# MSS_CTRL_MSS_CTRL_50D00000h register map
Vendor: Texas Instruments
Registers are 32-bit, read-only, reset values left out (the file's numbers can be read two ways) unless marked. A register's access mark holds for its fields unless they carry their own. Offsets are as the file gives them; [hi:lo] are bit positions.

## MSS_CTRL (part 5 of 10)
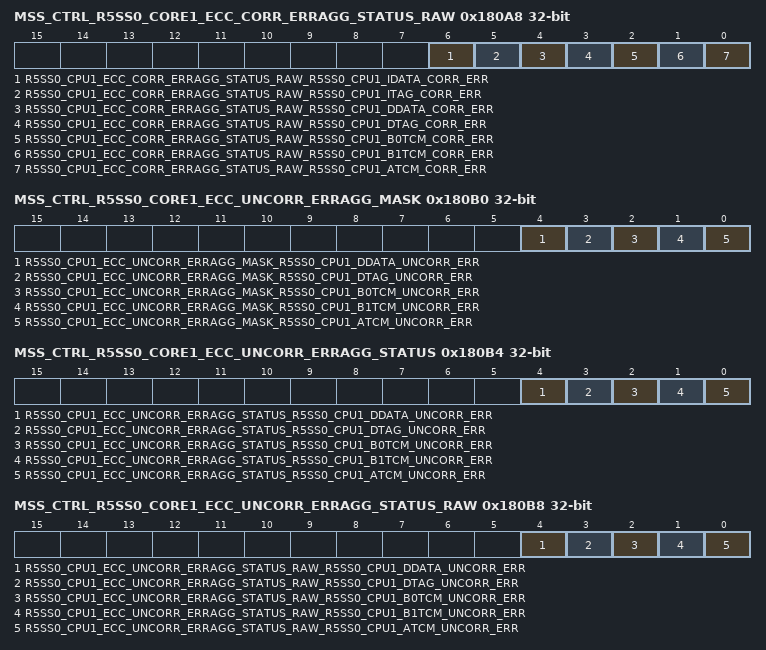
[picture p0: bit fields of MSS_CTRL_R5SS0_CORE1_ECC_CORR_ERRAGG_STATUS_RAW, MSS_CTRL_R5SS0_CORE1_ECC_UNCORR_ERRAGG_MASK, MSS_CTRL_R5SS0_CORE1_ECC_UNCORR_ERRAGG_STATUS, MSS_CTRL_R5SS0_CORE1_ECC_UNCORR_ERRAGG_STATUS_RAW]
0x180A8 MSS_CTRL_R5SS0_CORE1_ECC_CORR_ERRAGG_STATUS_RAW rw — Raw status for correctable error from R5SS0 CORE1 Memories.
  [6] R5SS0_CPU1_ECC_CORR_ERRAGG_STATUS_RAW_R5SS0_CPU1_IDATA_CORR_ERR — Raw Status of Interrupt from correctable error of corresponding CPUSet only if Interupt is unmasked in corresponding R5SS*_CPU*_ECC_CORR_ERRAGG_MASK registerWrie 0x1 to clear this interrupt.
  [5] R5SS0_CPU1_ECC_CORR_ERRAGG_STATUS_RAW_R5SS0_CPU1_ITAG_CORR_ERR — Raw Status of Interrupt from correctable error of corresponding CPUSet only if Interupt is unmasked in corresponding R5SS*_CPU*_ECC_CORR_ERRAGG_MASK registerWrie 0x1 to clear this interrupt.
  [4] R5SS0_CPU1_ECC_CORR_ERRAGG_STATUS_RAW_R5SS0_CPU1_DDATA_CORR_ERR — Raw Status of Interrupt from correctable error of corresponding CPUSet only if Interupt is unmasked in corresponding R5SS*_CPU*_ECC_CORR_ERRAGG_MASK registerWrie 0x1 to clear this interrupt.
  [3] R5SS0_CPU1_ECC_CORR_ERRAGG_STATUS_RAW_R5SS0_CPU1_DTAG_CORR_ERR — Raw Status of Interrupt from correctable error of corresponding CPUSet only if Interupt is unmasked in corresponding R5SS*_CPU*_ECC_CORR_ERRAGG_MASK registerWrie 0x1 to clear this interrupt.
  [2] R5SS0_CPU1_ECC_CORR_ERRAGG_STATUS_RAW_R5SS0_CPU1_B0TCM_CORR_ERR — Raw Status of Interrupt from correctable error of corresponding CPUSet only if Interupt is unmasked in corresponding R5SS*_CPU*_ECC_CORR_ERRAGG_MASK registerWrie 0x1 to clear this interrupt.
  [1] R5SS0_CPU1_ECC_CORR_ERRAGG_STATUS_RAW_R5SS0_CPU1_B1TCM_CORR_ERR — Raw Status of Interrupt from correctable error of corresponding CPUSet only if Interupt is unmasked in corresponding R5SS*_CPU*_ECC_CORR_ERRAGG_MASK registerWrie 0x1 to clear this interrupt.
  [0] R5SS0_CPU1_ECC_CORR_ERRAGG_STATUS_RAW_R5SS0_CPU1_ATCM_CORR_ERR — Raw Status of Interrupt from correctable error of corresponding CPUSet only if Interupt is unmasked in corresponding R5SS*_CPU*_ECC_CORR_ERRAGG_MASK registerWrie 0x1 to clear this interrupt.
0x180B0 MSS_CTRL_R5SS0_CORE1_ECC_UNCORR_ERRAGG_MASK rw — Register to Mask Uncorrectable error from R5SS0 CORE1 Memories.
  [4] R5SS0_CPU1_ECC_UNCORR_ERRAGG_MASK_R5SS0_CPU1_DDATA_UNCORR_ERR — Mask Interrupt for correctable errors to aggregated Interrupt of corresponding CPU1'b1 : Interrupt is Masked1'b0 : Interrupt is Unmasked
  [3] R5SS0_CPU1_ECC_UNCORR_ERRAGG_MASK_R5SS0_CPU1_DTAG_UNCORR_ERR — Mask Interrupt for correctable errors to aggregated Interrupt of corresponding CPU1'b1 : Interrupt is Masked1'b0 : Interrupt is Unmasked
  [2] R5SS0_CPU1_ECC_UNCORR_ERRAGG_MASK_R5SS0_CPU1_B0TCM_UNCORR_ERR — Mask Interrupt for correctable errors to aggregated Interrupt of corresponding CPU1'b1 : Interrupt is Masked1'b0 : Interrupt is Unmasked
  [1] R5SS0_CPU1_ECC_UNCORR_ERRAGG_MASK_R5SS0_CPU1_B1TCM_UNCORR_ERR — Mask Interrupt for correctable errors to aggregated Interrupt of corresponding CPU1'b1 : Interrupt is Masked1'b0 : Interrupt is Unmasked
  [0] R5SS0_CPU1_ECC_UNCORR_ERRAGG_MASK_R5SS0_CPU1_ATCM_UNCORR_ERR — Mask Interrupt for correctable errors to aggregated Interrupt of corresponding CPU1'b1 : Interrupt is Masked1'b0 : Interrupt is Unmasked
0x180B4 MSS_CTRL_R5SS0_CORE1_ECC_UNCORR_ERRAGG_STATUS rw — Status register based on mask for uncorrectable error R5SS0 CORE1 Memories.
  [4] R5SS0_CPU1_ECC_UNCORR_ERRAGG_STATUS_R5SS0_CPU1_DDATA_UNCORR_ERR — Status of Interrupt from correctable error of corresponding CPUSet only if Interupt is unmasked in corresponding R5SS*_CPU*_ECC_UNCORR_ERRAGG_MASK registerWrie 0x1 to clear this interrupt.
  [3] R5SS0_CPU1_ECC_UNCORR_ERRAGG_STATUS_R5SS0_CPU1_DTAG_UNCORR_ERR — Status of Interrupt from correctable error of corresponding CPUSet only if Interupt is unmasked in corresponding R5SS*_CPU*_ECC_UNCORR_ERRAGG_MASK registerWrie 0x1 to clear this interrupt.
  [2] R5SS0_CPU1_ECC_UNCORR_ERRAGG_STATUS_R5SS0_CPU1_B0TCM_UNCORR_ERR — Status of Interrupt from correctable error of corresponding CPUSet only if Interupt is unmasked in corresponding R5SS*_CPU*_ECC_UNCORR_ERRAGG_MASK registerWrie 0x1 to clear this interrupt.
  [1] R5SS0_CPU1_ECC_UNCORR_ERRAGG_STATUS_R5SS0_CPU1_B1TCM_UNCORR_ERR — Status of Interrupt from correctable error of corresponding CPUSet only if Interupt is unmasked in corresponding R5SS*_CPU*_ECC_UNCORR_ERRAGG_MASK registerWrie 0x1 to clear this interrupt.
  [0] R5SS0_CPU1_ECC_UNCORR_ERRAGG_STATUS_R5SS0_CPU1_ATCM_UNCORR_ERR — Status of Interrupt from correctable error of corresponding CPUSet only if Interupt is unmasked in corresponding R5SS*_CPU*_ECC_UNCORR_ERRAGG_MASK registerWrie 0x1 to clear this interrupt.
0x180B8 MSS_CTRL_R5SS0_CORE1_ECC_UNCORR_ERRAGG_STATUS_RAW rw — Raw status for uncorrectable error from R5SS0 CORE1 Memories.
  [4] R5SS0_CPU1_ECC_UNCORR_ERRAGG_STATUS_RAW_R5SS0_CPU1_DDATA_UNCORR_ERR — Raw Status of Interrupt from correctable error of corresponding CPUSet only if Interupt is unmasked in corresponding R5SS*_CPU*_ECC_UNCORR_ERRAGG_MASK registerWrie 0x1 to clear this interrupt.
  [3] R5SS0_CPU1_ECC_UNCORR_ERRAGG_STATUS_RAW_R5SS0_CPU1_DTAG_UNCORR_ERR — Raw Status of Interrupt from correctable error of corresponding CPUSet only if Interupt is unmasked in corresponding R5SS*_CPU*_ECC_UNCORR_ERRAGG_MASK registerWrie 0x1 to clear this interrupt.
  [2] R5SS0_CPU1_ECC_UNCORR_ERRAGG_STATUS_RAW_R5SS0_CPU1_B0TCM_UNCORR_ERR — Raw Status of Interrupt from correctable error of corresponding CPUSet only if Interupt is unmasked in corresponding R5SS*_CPU*_ECC_UNCORR_ERRAGG_MASK registerWrie 0x1 to clear this interrupt.
  [1] R5SS0_CPU1_ECC_UNCORR_ERRAGG_STATUS_RAW_R5SS0_CPU1_B1TCM_UNCORR_ERR — Raw Status of Interrupt from correctable error of corresponding CPUSet only if Interupt is unmasked in corresponding R5SS*_CPU*_ECC_UNCORR_ERRAGG_MASK registerWrie 0x1 to clear this interrupt.
  [0] R5SS0_CPU1_ECC_UNCORR_ERRAGG_STATUS_RAW_R5SS0_CPU1_ATCM_UNCORR_ERR — Raw Status of Interrupt from correctable error of corresponding CPUSet only if Interupt is unmasked in corresponding R5SS*_CPU*_ECC_UNCORR_ERRAGG_MASK registerWrie 0x1 to clear this interrupt.
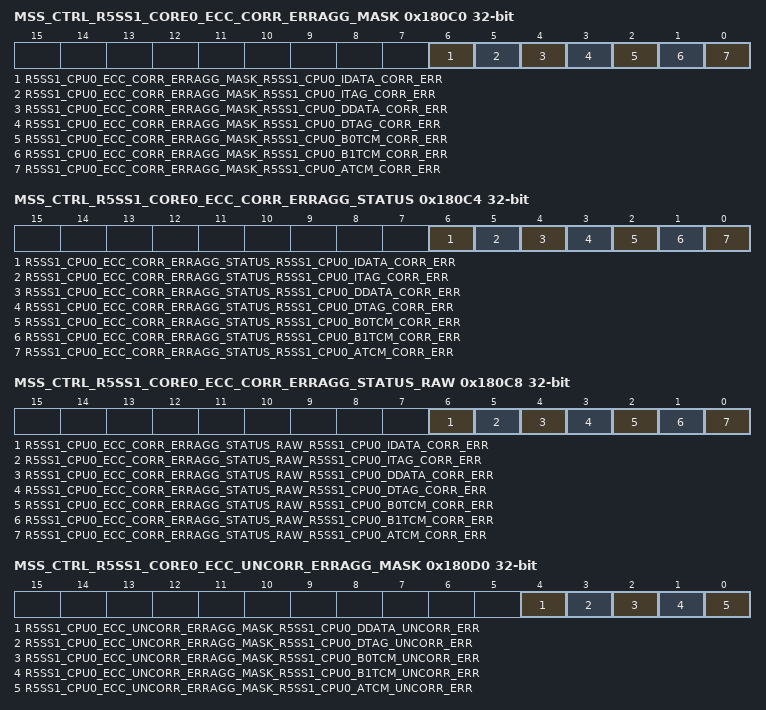
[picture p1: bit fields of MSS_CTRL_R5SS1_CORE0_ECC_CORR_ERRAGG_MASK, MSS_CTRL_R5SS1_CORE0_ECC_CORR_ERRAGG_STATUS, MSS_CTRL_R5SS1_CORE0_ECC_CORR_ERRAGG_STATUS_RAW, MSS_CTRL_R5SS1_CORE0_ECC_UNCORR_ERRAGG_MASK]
0x180C0 MSS_CTRL_R5SS1_CORE0_ECC_CORR_ERRAGG_MASK rw — Register to Mask Correctable error from R5SS1 CORE0 Memories.
  [6] R5SS1_CPU0_ECC_CORR_ERRAGG_MASK_R5SS1_CPU0_IDATA_CORR_ERR — Mask Interrupt for correctable errors to aggregated Interrupt of corresponding CPU1'b1 : Interrupt is Masked1'b0 : Interrupt is Unmasked
  [5] R5SS1_CPU0_ECC_CORR_ERRAGG_MASK_R5SS1_CPU0_ITAG_CORR_ERR — Mask Interrupt for correctable errors to aggregated Interrupt of corresponding CPU1'b1 : Interrupt is Masked1'b0 : Interrupt is Unmasked
  [4] R5SS1_CPU0_ECC_CORR_ERRAGG_MASK_R5SS1_CPU0_DDATA_CORR_ERR — Mask Interrupt for correctable errors to aggregated Interrupt of corresponding CPU1'b1 : Interrupt is Masked1'b0 : Interrupt is Unmasked
  [3] R5SS1_CPU0_ECC_CORR_ERRAGG_MASK_R5SS1_CPU0_DTAG_CORR_ERR — Mask Interrupt for correctable errors to aggregated Interrupt of corresponding CPU1'b1 : Interrupt is Masked1'b0 : Interrupt is Unmasked
  [2] R5SS1_CPU0_ECC_CORR_ERRAGG_MASK_R5SS1_CPU0_B0TCM_CORR_ERR — Mask Interrupt for correctable errors to aggregated Interrupt of corresponding CPU1'b1 : Interrupt is Masked1'b0 : Interrupt is Unmasked
  [1] R5SS1_CPU0_ECC_CORR_ERRAGG_MASK_R5SS1_CPU0_B1TCM_CORR_ERR — Mask Interrupt for correctable errors to aggregated Interrupt of corresponding CPU1'b1 : Interrupt is Masked1'b0 : Interrupt is Unmasked
  [0] R5SS1_CPU0_ECC_CORR_ERRAGG_MASK_R5SS1_CPU0_ATCM_CORR_ERR — Mask Interrupt for correctable errors to aggregated Interrupt of corresponding CPU1'b1 : Interrupt is Masked1'b0 : Interrupt is Unmasked
0x180C4 MSS_CTRL_R5SS1_CORE0_ECC_CORR_ERRAGG_STATUS rw — Status register based on mask for correctable error R5SS1 CORE0 Memories.
  [6] R5SS1_CPU0_ECC_CORR_ERRAGG_STATUS_R5SS1_CPU0_IDATA_CORR_ERR — Status of Interrupt from correctable error of corresponding CPUSet only if Interupt is unmasked in corresponding R5SS*_CPU*_ECC_CORR_ERRAGG_MASK registerWrie 0x1 to clear this interrupt.
  [5] R5SS1_CPU0_ECC_CORR_ERRAGG_STATUS_R5SS1_CPU0_ITAG_CORR_ERR — Status of Interrupt from correctable error of corresponding CPUSet only if Interupt is unmasked in corresponding R5SS*_CPU*_ECC_CORR_ERRAGG_MASK registerWrie 0x1 to clear this interrupt.
  [4] R5SS1_CPU0_ECC_CORR_ERRAGG_STATUS_R5SS1_CPU0_DDATA_CORR_ERR — Status of Interrupt from correctable error of corresponding CPUSet only if Interupt is unmasked in corresponding R5SS*_CPU*_ECC_CORR_ERRAGG_MASK registerWrie 0x1 to clear this interrupt.
  [3] R5SS1_CPU0_ECC_CORR_ERRAGG_STATUS_R5SS1_CPU0_DTAG_CORR_ERR — Status of Interrupt from correctable error of corresponding CPUSet only if Interupt is unmasked in corresponding R5SS*_CPU*_ECC_CORR_ERRAGG_MASK registerWrie 0x1 to clear this interrupt.
  [2] R5SS1_CPU0_ECC_CORR_ERRAGG_STATUS_R5SS1_CPU0_B0TCM_CORR_ERR — Status of Interrupt from correctable error of corresponding CPUSet only if Interupt is unmasked in corresponding R5SS*_CPU*_ECC_CORR_ERRAGG_MASK registerWrie 0x1 to clear this interrupt.
  [1] R5SS1_CPU0_ECC_CORR_ERRAGG_STATUS_R5SS1_CPU0_B1TCM_CORR_ERR — Status of Interrupt from correctable error of corresponding CPUSet only if Interupt is unmasked in corresponding R5SS*_CPU*_ECC_CORR_ERRAGG_MASK registerWrie 0x1 to clear this interrupt.
  [0] R5SS1_CPU0_ECC_CORR_ERRAGG_STATUS_R5SS1_CPU0_ATCM_CORR_ERR — Status of Interrupt from correctable error of corresponding CPUSet only if Interupt is unmasked in corresponding R5SS*_CPU*_ECC_CORR_ERRAGG_MASK registerWrie 0x1 to clear this interrupt.
0x180C8 MSS_CTRL_R5SS1_CORE0_ECC_CORR_ERRAGG_STATUS_RAW rw — Raw status for correctable error from R5SS1 CORE0 Memories.
  [6] R5SS1_CPU0_ECC_CORR_ERRAGG_STATUS_RAW_R5SS1_CPU0_IDATA_CORR_ERR — Raw Status of Interrupt from correctable error of corresponding CPUSet only if Interupt is unmasked in corresponding R5SS*_CPU*_ECC_CORR_ERRAGG_MASK registerWrie 0x1 to clear this interrupt.
  [5] R5SS1_CPU0_ECC_CORR_ERRAGG_STATUS_RAW_R5SS1_CPU0_ITAG_CORR_ERR — Raw Status of Interrupt from correctable error of corresponding CPUSet only if Interupt is unmasked in corresponding R5SS*_CPU*_ECC_CORR_ERRAGG_MASK registerWrie 0x1 to clear this interrupt.
  [4] R5SS1_CPU0_ECC_CORR_ERRAGG_STATUS_RAW_R5SS1_CPU0_DDATA_CORR_ERR — Raw Status of Interrupt from correctable error of corresponding CPUSet only if Interupt is unmasked in corresponding R5SS*_CPU*_ECC_CORR_ERRAGG_MASK registerWrie 0x1 to clear this interrupt.
  [3] R5SS1_CPU0_ECC_CORR_ERRAGG_STATUS_RAW_R5SS1_CPU0_DTAG_CORR_ERR — Raw Status of Interrupt from correctable error of corresponding CPUSet only if Interupt is unmasked in corresponding R5SS*_CPU*_ECC_CORR_ERRAGG_MASK registerWrie 0x1 to clear this interrupt.
  [2] R5SS1_CPU0_ECC_CORR_ERRAGG_STATUS_RAW_R5SS1_CPU0_B0TCM_CORR_ERR — Raw Status of Interrupt from correctable error of corresponding CPUSet only if Interupt is unmasked in corresponding R5SS*_CPU*_ECC_CORR_ERRAGG_MASK registerWrie 0x1 to clear this interrupt.
  [1] R5SS1_CPU0_ECC_CORR_ERRAGG_STATUS_RAW_R5SS1_CPU0_B1TCM_CORR_ERR — Raw Status of Interrupt from correctable error of corresponding CPUSet only if Interupt is unmasked in corresponding R5SS*_CPU*_ECC_CORR_ERRAGG_MASK registerWrie 0x1 to clear this interrupt.
  [0] R5SS1_CPU0_ECC_CORR_ERRAGG_STATUS_RAW_R5SS1_CPU0_ATCM_CORR_ERR — Raw Status of Interrupt from correctable error of corresponding CPUSet only if Interupt is unmasked in corresponding R5SS*_CPU*_ECC_CORR_ERRAGG_MASK registerWrie 0x1 to clear this interrupt.
0x180D0 MSS_CTRL_R5SS1_CORE0_ECC_UNCORR_ERRAGG_MASK rw — Register to Mask Uncorrectable error from R5SS1 CORE0 Memories.
  [4] R5SS1_CPU0_ECC_UNCORR_ERRAGG_MASK_R5SS1_CPU0_DDATA_UNCORR_ERR — Mask Interrupt for correctable errors to aggregated Interrupt of corresponding CPU1'b1 : Interrupt is Masked1'b0 : Interrupt is Unmasked
  [3] R5SS1_CPU0_ECC_UNCORR_ERRAGG_MASK_R5SS1_CPU0_DTAG_UNCORR_ERR — Mask Interrupt for correctable errors to aggregated Interrupt of corresponding CPU1'b1 : Interrupt is Masked1'b0 : Interrupt is Unmasked
  [2] R5SS1_CPU0_ECC_UNCORR_ERRAGG_MASK_R5SS1_CPU0_B0TCM_UNCORR_ERR — Mask Interrupt for correctable errors to aggregated Interrupt of corresponding CPU1'b1 : Interrupt is Masked1'b0 : Interrupt is Unmasked
  [1] R5SS1_CPU0_ECC_UNCORR_ERRAGG_MASK_R5SS1_CPU0_B1TCM_UNCORR_ERR — Mask Interrupt for correctable errors to aggregated Interrupt of corresponding CPU1'b1 : Interrupt is Masked1'b0 : Interrupt is Unmasked
  [0] R5SS1_CPU0_ECC_UNCORR_ERRAGG_MASK_R5SS1_CPU0_ATCM_UNCORR_ERR — Mask Interrupt for correctable errors to aggregated Interrupt of corresponding CPU1'b1 : Interrupt is Masked1'b0 : Interrupt is Unmasked
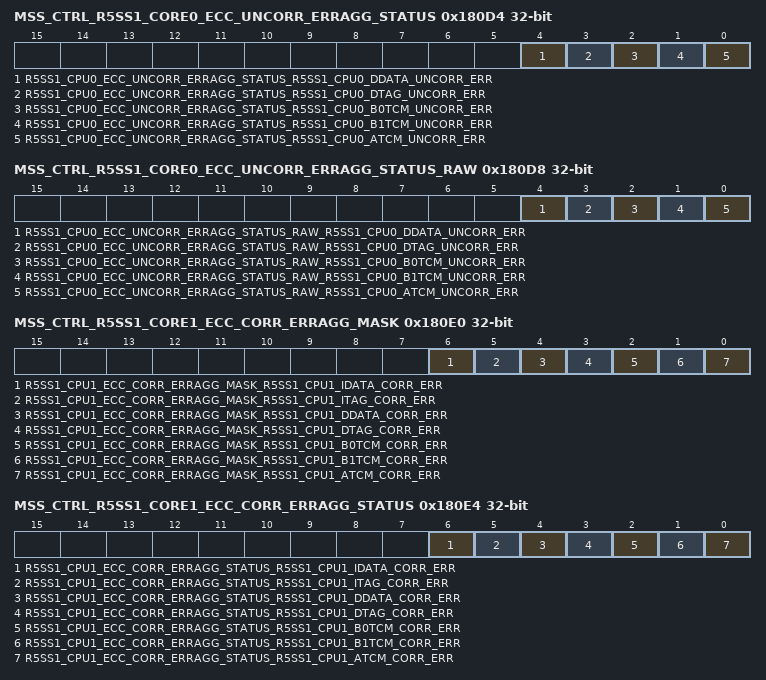
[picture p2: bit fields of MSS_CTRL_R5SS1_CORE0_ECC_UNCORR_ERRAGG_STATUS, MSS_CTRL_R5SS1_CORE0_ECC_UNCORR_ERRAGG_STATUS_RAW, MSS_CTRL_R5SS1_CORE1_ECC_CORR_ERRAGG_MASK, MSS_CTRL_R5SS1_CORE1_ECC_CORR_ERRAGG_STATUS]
0x180D4 MSS_CTRL_R5SS1_CORE0_ECC_UNCORR_ERRAGG_STATUS rw — Status register based on mask for uncorrectable error R5SS1 CORE0 Memories.
  [4] R5SS1_CPU0_ECC_UNCORR_ERRAGG_STATUS_R5SS1_CPU0_DDATA_UNCORR_ERR — Status of Interrupt from correctable error of corresponding CPUSet only if Interupt is unmasked in corresponding R5SS*_CPU*_ECC_UNCORR_ERRAGG_MASK registerWrie 0x1 to clear this interrupt.
  [3] R5SS1_CPU0_ECC_UNCORR_ERRAGG_STATUS_R5SS1_CPU0_DTAG_UNCORR_ERR — Status of Interrupt from correctable error of corresponding CPUSet only if Interupt is unmasked in corresponding R5SS*_CPU*_ECC_UNCORR_ERRAGG_MASK registerWrie 0x1 to clear this interrupt.
  [2] R5SS1_CPU0_ECC_UNCORR_ERRAGG_STATUS_R5SS1_CPU0_B0TCM_UNCORR_ERR — Status of Interrupt from correctable error of corresponding CPUSet only if Interupt is unmasked in corresponding R5SS*_CPU*_ECC_UNCORR_ERRAGG_MASK registerWrie 0x1 to clear this interrupt.
  [1] R5SS1_CPU0_ECC_UNCORR_ERRAGG_STATUS_R5SS1_CPU0_B1TCM_UNCORR_ERR — Status of Interrupt from correctable error of corresponding CPUSet only if Interupt is unmasked in corresponding R5SS*_CPU*_ECC_UNCORR_ERRAGG_MASK registerWrie 0x1 to clear this interrupt.
  [0] R5SS1_CPU0_ECC_UNCORR_ERRAGG_STATUS_R5SS1_CPU0_ATCM_UNCORR_ERR — Status of Interrupt from correctable error of corresponding CPUSet only if Interupt is unmasked in corresponding R5SS*_CPU*_ECC_UNCORR_ERRAGG_MASK registerWrie 0x1 to clear this interrupt.
0x180D8 MSS_CTRL_R5SS1_CORE0_ECC_UNCORR_ERRAGG_STATUS_RAW rw — Raw status for uncorrectable error from R5SS1 CORE0 Memories.
  [4] R5SS1_CPU0_ECC_UNCORR_ERRAGG_STATUS_RAW_R5SS1_CPU0_DDATA_UNCORR_ERR — Raw Status of Interrupt from correctable error of corresponding CPUSet only if Interupt is unmasked in corresponding R5SS*_CPU*_ECC_UNCORR_ERRAGG_MASK registerWrie 0x1 to clear this interrupt.
  [3] R5SS1_CPU0_ECC_UNCORR_ERRAGG_STATUS_RAW_R5SS1_CPU0_DTAG_UNCORR_ERR — Raw Status of Interrupt from correctable error of corresponding CPUSet only if Interupt is unmasked in corresponding R5SS*_CPU*_ECC_UNCORR_ERRAGG_MASK registerWrie 0x1 to clear this interrupt.
  [2] R5SS1_CPU0_ECC_UNCORR_ERRAGG_STATUS_RAW_R5SS1_CPU0_B0TCM_UNCORR_ERR — Raw Status of Interrupt from correctable error of corresponding CPUSet only if Interupt is unmasked in corresponding R5SS*_CPU*_ECC_UNCORR_ERRAGG_MASK registerWrie 0x1 to clear this interrupt.
  [1] R5SS1_CPU0_ECC_UNCORR_ERRAGG_STATUS_RAW_R5SS1_CPU0_B1TCM_UNCORR_ERR — Raw Status of Interrupt from correctable error of corresponding CPUSet only if Interupt is unmasked in corresponding R5SS*_CPU*_ECC_UNCORR_ERRAGG_MASK registerWrie 0x1 to clear this interrupt.
  [0] R5SS1_CPU0_ECC_UNCORR_ERRAGG_STATUS_RAW_R5SS1_CPU0_ATCM_UNCORR_ERR — Raw Status of Interrupt from correctable error of corresponding CPUSet only if Interupt is unmasked in corresponding R5SS*_CPU*_ECC_UNCORR_ERRAGG_MASK registerWrie 0x1 to clear this interrupt.
0x180E0 MSS_CTRL_R5SS1_CORE1_ECC_CORR_ERRAGG_MASK rw — Register to Mask Correctable error from R5SS1 CORE1 Memories.
  [6] R5SS1_CPU1_ECC_CORR_ERRAGG_MASK_R5SS1_CPU1_IDATA_CORR_ERR — Mask Interrupt for correctable errors to aggregated Interrupt of corresponding CPU1'b1 : Interrupt is Masked1'b0 : Interrupt is Unmasked
  [5] R5SS1_CPU1_ECC_CORR_ERRAGG_MASK_R5SS1_CPU1_ITAG_CORR_ERR — Mask Interrupt for correctable errors to aggregated Interrupt of corresponding CPU1'b1 : Interrupt is Masked1'b0 : Interrupt is Unmasked
  [4] R5SS1_CPU1_ECC_CORR_ERRAGG_MASK_R5SS1_CPU1_DDATA_CORR_ERR — Mask Interrupt for correctable errors to aggregated Interrupt of corresponding CPU1'b1 : Interrupt is Masked1'b0 : Interrupt is Unmasked
  [3] R5SS1_CPU1_ECC_CORR_ERRAGG_MASK_R5SS1_CPU1_DTAG_CORR_ERR — Mask Interrupt for correctable errors to aggregated Interrupt of corresponding CPU1'b1 : Interrupt is Masked1'b0 : Interrupt is Unmasked
  [2] R5SS1_CPU1_ECC_CORR_ERRAGG_MASK_R5SS1_CPU1_B0TCM_CORR_ERR — Mask Interrupt for correctable errors to aggregated Interrupt of corresponding CPU1'b1 : Interrupt is Masked1'b0 : Interrupt is Unmasked
  [1] R5SS1_CPU1_ECC_CORR_ERRAGG_MASK_R5SS1_CPU1_B1TCM_CORR_ERR — Mask Interrupt for correctable errors to aggregated Interrupt of corresponding CPU1'b1 : Interrupt is Masked1'b0 : Interrupt is Unmasked
  [0] R5SS1_CPU1_ECC_CORR_ERRAGG_MASK_R5SS1_CPU1_ATCM_CORR_ERR — Mask Interrupt for correctable errors to aggregated Interrupt of corresponding CPU1'b1 : Interrupt is Masked1'b0 : Interrupt is Unmasked
0x180E4 MSS_CTRL_R5SS1_CORE1_ECC_CORR_ERRAGG_STATUS rw — Status register based on mask for correctable error R5SS1 CORE1 Memories.
  [6] R5SS1_CPU1_ECC_CORR_ERRAGG_STATUS_R5SS1_CPU1_IDATA_CORR_ERR — Status of Interrupt from correctable error of corresponding CPUSet only if Interupt is unmasked in corresponding R5SS*_CPU*_ECC_CORR_ERRAGG_MASK registerWrie 0x1 to clear this interrupt.
  [5] R5SS1_CPU1_ECC_CORR_ERRAGG_STATUS_R5SS1_CPU1_ITAG_CORR_ERR — Status of Interrupt from correctable error of corresponding CPUSet only if Interupt is unmasked in corresponding R5SS*_CPU*_ECC_CORR_ERRAGG_MASK registerWrie 0x1 to clear this interrupt.
  [4] R5SS1_CPU1_ECC_CORR_ERRAGG_STATUS_R5SS1_CPU1_DDATA_CORR_ERR — Status of Interrupt from correctable error of corresponding CPUSet only if Interupt is unmasked in corresponding R5SS*_CPU*_ECC_CORR_ERRAGG_MASK registerWrie 0x1 to clear this interrupt.
  [3] R5SS1_CPU1_ECC_CORR_ERRAGG_STATUS_R5SS1_CPU1_DTAG_CORR_ERR — Status of Interrupt from correctable error of corresponding CPUSet only if Interupt is unmasked in corresponding R5SS*_CPU*_ECC_CORR_ERRAGG_MASK registerWrie 0x1 to clear this interrupt.
  [2] R5SS1_CPU1_ECC_CORR_ERRAGG_STATUS_R5SS1_CPU1_B0TCM_CORR_ERR — Status of Interrupt from correctable error of corresponding CPUSet only if Interupt is unmasked in corresponding R5SS*_CPU*_ECC_CORR_ERRAGG_MASK registerWrie 0x1 to clear this interrupt.
  [1] R5SS1_CPU1_ECC_CORR_ERRAGG_STATUS_R5SS1_CPU1_B1TCM_CORR_ERR — Status of Interrupt from correctable error of corresponding CPUSet only if Interupt is unmasked in corresponding R5SS*_CPU*_ECC_CORR_ERRAGG_MASK registerWrie 0x1 to clear this interrupt.
  [0] R5SS1_CPU1_ECC_CORR_ERRAGG_STATUS_R5SS1_CPU1_ATCM_CORR_ERR — Status of Interrupt from correctable error of corresponding CPUSet only if Interupt is unmasked in corresponding R5SS*_CPU*_ECC_CORR_ERRAGG_MASK registerWrie 0x1 to clear this interrupt.
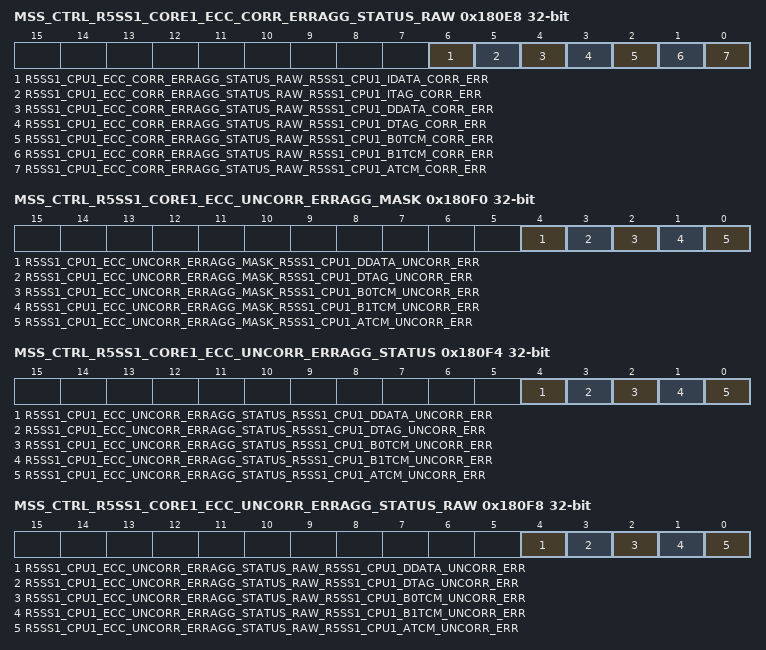
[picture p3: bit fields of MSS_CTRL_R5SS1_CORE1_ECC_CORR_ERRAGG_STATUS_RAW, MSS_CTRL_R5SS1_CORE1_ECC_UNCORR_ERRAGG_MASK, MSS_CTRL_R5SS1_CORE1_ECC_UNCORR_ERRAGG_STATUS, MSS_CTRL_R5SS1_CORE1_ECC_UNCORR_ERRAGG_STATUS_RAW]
0x180E8 MSS_CTRL_R5SS1_CORE1_ECC_CORR_ERRAGG_STATUS_RAW rw — Raw status for correctable error from R5SS1 CORE1 Memories.
  [6] R5SS1_CPU1_ECC_CORR_ERRAGG_STATUS_RAW_R5SS1_CPU1_IDATA_CORR_ERR — Raw Status of Interrupt from correctable error of corresponding CPUSet only if Interupt is unmasked in corresponding R5SS*_CPU*_ECC_CORR_ERRAGG_MASK registerWrie 0x1 to clear this interrupt.
  [5] R5SS1_CPU1_ECC_CORR_ERRAGG_STATUS_RAW_R5SS1_CPU1_ITAG_CORR_ERR — Raw Status of Interrupt from correctable error of corresponding CPUSet only if Interupt is unmasked in corresponding R5SS*_CPU*_ECC_CORR_ERRAGG_MASK registerWrie 0x1 to clear this interrupt.
  [4] R5SS1_CPU1_ECC_CORR_ERRAGG_STATUS_RAW_R5SS1_CPU1_DDATA_CORR_ERR — Raw Status of Interrupt from correctable error of corresponding CPUSet only if Interupt is unmasked in corresponding R5SS*_CPU*_ECC_CORR_ERRAGG_MASK registerWrie 0x1 to clear this interrupt.
  [3] R5SS1_CPU1_ECC_CORR_ERRAGG_STATUS_RAW_R5SS1_CPU1_DTAG_CORR_ERR — Raw Status of Interrupt from correctable error of corresponding CPUSet only if Interupt is unmasked in corresponding R5SS*_CPU*_ECC_CORR_ERRAGG_MASK registerWrie 0x1 to clear this interrupt.
  [2] R5SS1_CPU1_ECC_CORR_ERRAGG_STATUS_RAW_R5SS1_CPU1_B0TCM_CORR_ERR — Raw Status of Interrupt from correctable error of corresponding CPUSet only if Interupt is unmasked in corresponding R5SS*_CPU*_ECC_CORR_ERRAGG_MASK registerWrie 0x1 to clear this interrupt.
  [1] R5SS1_CPU1_ECC_CORR_ERRAGG_STATUS_RAW_R5SS1_CPU1_B1TCM_CORR_ERR — Raw Status of Interrupt from correctable error of corresponding CPUSet only if Interupt is unmasked in corresponding R5SS*_CPU*_ECC_CORR_ERRAGG_MASK registerWrie 0x1 to clear this interrupt.
  [0] R5SS1_CPU1_ECC_CORR_ERRAGG_STATUS_RAW_R5SS1_CPU1_ATCM_CORR_ERR — Raw Status of Interrupt from correctable error of corresponding CPUSet only if Interupt is unmasked in corresponding R5SS*_CPU*_ECC_CORR_ERRAGG_MASK registerWrie 0x1 to clear this interrupt.
0x180F0 MSS_CTRL_R5SS1_CORE1_ECC_UNCORR_ERRAGG_MASK rw — Register to Mask Uncorrectable error from R5SS1 CORE1 Memories.
  [4] R5SS1_CPU1_ECC_UNCORR_ERRAGG_MASK_R5SS1_CPU1_DDATA_UNCORR_ERR — Mask Interrupt for correctable errors to aggregated Interrupt of corresponding CPU1'b1 : Interrupt is Masked1'b0 : Interrupt is Unmasked
  [3] R5SS1_CPU1_ECC_UNCORR_ERRAGG_MASK_R5SS1_CPU1_DTAG_UNCORR_ERR — Mask Interrupt for correctable errors to aggregated Interrupt of corresponding CPU1'b1 : Interrupt is Masked1'b0 : Interrupt is Unmasked
  [2] R5SS1_CPU1_ECC_UNCORR_ERRAGG_MASK_R5SS1_CPU1_B0TCM_UNCORR_ERR — Mask Interrupt for correctable errors to aggregated Interrupt of corresponding CPU1'b1 : Interrupt is Masked1'b0 : Interrupt is Unmasked
  [1] R5SS1_CPU1_ECC_UNCORR_ERRAGG_MASK_R5SS1_CPU1_B1TCM_UNCORR_ERR — Mask Interrupt for correctable errors to aggregated Interrupt of corresponding CPU1'b1 : Interrupt is Masked1'b0 : Interrupt is Unmasked
  [0] R5SS1_CPU1_ECC_UNCORR_ERRAGG_MASK_R5SS1_CPU1_ATCM_UNCORR_ERR — Mask Interrupt for correctable errors to aggregated Interrupt of corresponding CPU1'b1 : Interrupt is Masked1'b0 : Interrupt is Unmasked
0x180F4 MSS_CTRL_R5SS1_CORE1_ECC_UNCORR_ERRAGG_STATUS rw — Status register based on mask for uncorrectable error R5SS1 CORE1 Memories.
  [4] R5SS1_CPU1_ECC_UNCORR_ERRAGG_STATUS_R5SS1_CPU1_DDATA_UNCORR_ERR — Status of Interrupt from correctable error of corresponding CPUSet only if Interupt is unmasked in corresponding R5SS*_CPU*_ECC_UNCORR_ERRAGG_MASK registerWrie 0x1 to clear this interrupt.
  [3] R5SS1_CPU1_ECC_UNCORR_ERRAGG_STATUS_R5SS1_CPU1_DTAG_UNCORR_ERR — Status of Interrupt from correctable error of corresponding CPUSet only if Interupt is unmasked in corresponding R5SS*_CPU*_ECC_UNCORR_ERRAGG_MASK registerWrie 0x1 to clear this interrupt.
  [2] R5SS1_CPU1_ECC_UNCORR_ERRAGG_STATUS_R5SS1_CPU1_B0TCM_UNCORR_ERR — Status of Interrupt from correctable error of corresponding CPUSet only if Interupt is unmasked in corresponding R5SS*_CPU*_ECC_UNCORR_ERRAGG_MASK registerWrie 0x1 to clear this interrupt.
  [1] R5SS1_CPU1_ECC_UNCORR_ERRAGG_STATUS_R5SS1_CPU1_B1TCM_UNCORR_ERR — Status of Interrupt from correctable error of corresponding CPUSet only if Interupt is unmasked in corresponding R5SS*_CPU*_ECC_UNCORR_ERRAGG_MASK registerWrie 0x1 to clear this interrupt.
  [0] R5SS1_CPU1_ECC_UNCORR_ERRAGG_STATUS_R5SS1_CPU1_ATCM_UNCORR_ERR — Status of Interrupt from correctable error of corresponding CPUSet only if Interupt is unmasked in corresponding R5SS*_CPU*_ECC_UNCORR_ERRAGG_MASK registerWrie 0x1 to clear this interrupt.
0x180F8 MSS_CTRL_R5SS1_CORE1_ECC_UNCORR_ERRAGG_STATUS_RAW rw — Raw status for uncorrectable error from R5SS1 CORE1 Memories.
  [4] R5SS1_CPU1_ECC_UNCORR_ERRAGG_STATUS_RAW_R5SS1_CPU1_DDATA_UNCORR_ERR — Raw Status of Interrupt from correctable error of corresponding CPUSet only if Interupt is unmasked in corresponding R5SS*_CPU*_ECC_UNCORR_ERRAGG_MASK registerWrie 0x1 to clear this interrupt.
  [3] R5SS1_CPU1_ECC_UNCORR_ERRAGG_STATUS_RAW_R5SS1_CPU1_DTAG_UNCORR_ERR — Raw Status of Interrupt from correctable error of corresponding CPUSet only if Interupt is unmasked in corresponding R5SS*_CPU*_ECC_UNCORR_ERRAGG_MASK registerWrie 0x1 to clear this interrupt.
  [2] R5SS1_CPU1_ECC_UNCORR_ERRAGG_STATUS_RAW_R5SS1_CPU1_B0TCM_UNCORR_ERR — Raw Status of Interrupt from correctable error of corresponding CPUSet only if Interupt is unmasked in corresponding R5SS*_CPU*_ECC_UNCORR_ERRAGG_MASK registerWrie 0x1 to clear this interrupt.
  [1] R5SS1_CPU1_ECC_UNCORR_ERRAGG_STATUS_RAW_R5SS1_CPU1_B1TCM_UNCORR_ERR — Raw Status of Interrupt from correctable error of corresponding CPUSet only if Interupt is unmasked in corresponding R5SS*_CPU*_ECC_UNCORR_ERRAGG_MASK registerWrie 0x1 to clear this interrupt.
  [0] R5SS1_CPU1_ECC_UNCORR_ERRAGG_STATUS_RAW_R5SS1_CPU1_ATCM_UNCORR_ERR — Raw Status of Interrupt from correctable error of corresponding CPUSet only if Interupt is unmasked in corresponding R5SS*_CPU*_ECC_UNCORR_ERRAGG_MASK registerWrie 0x1 to clear this interrupt.
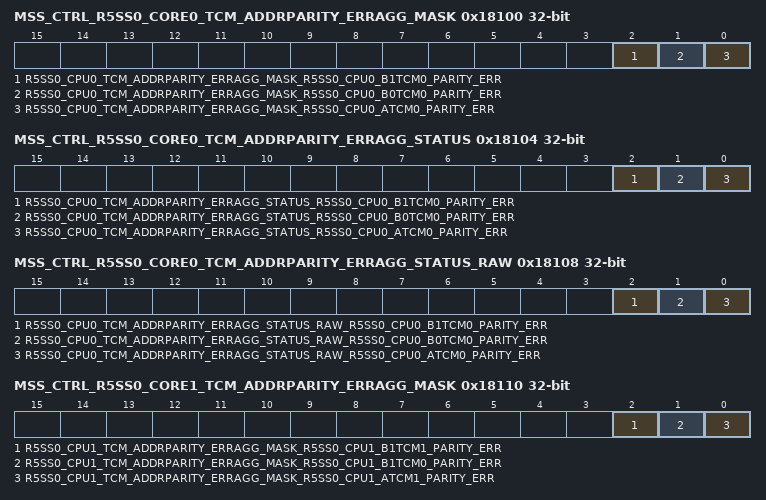
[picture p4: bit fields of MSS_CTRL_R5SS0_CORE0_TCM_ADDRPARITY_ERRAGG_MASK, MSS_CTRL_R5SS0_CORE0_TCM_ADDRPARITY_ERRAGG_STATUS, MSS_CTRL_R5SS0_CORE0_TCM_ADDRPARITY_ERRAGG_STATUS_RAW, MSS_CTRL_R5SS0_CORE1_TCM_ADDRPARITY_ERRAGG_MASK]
0x18100 MSS_CTRL_R5SS0_CORE0_TCM_ADDRPARITY_ERRAGG_MASK rw — Register to Mask TCM address parity errors from R5SS0 CORE0.
  [2] R5SS0_CPU0_TCM_ADDRPARITY_ERRAGG_MASK_R5SS0_CPU0_B1TCM0_PARITY_ERR — Mask Interrupt for address parity error s to aggregated Interrupt of corresponding CPU1'b1 : Interrupt is Masked1'b0 : Interrupt is Unmasked
  [1] R5SS0_CPU0_TCM_ADDRPARITY_ERRAGG_MASK_R5SS0_CPU0_B0TCM0_PARITY_ERR — Mask Interrupt for address parity error s to aggregated Interrupt of corresponding CPU1'b1 : Interrupt is Masked1'b0 : Interrupt is Unmasked
  [0] R5SS0_CPU0_TCM_ADDRPARITY_ERRAGG_MASK_R5SS0_CPU0_ATCM0_PARITY_ERR — Mask Interrupt for address parity error s to aggregated Interrupt of corresponding CPU1'b1 : Interrupt is Masked1'b0 : Interrupt is Unmasked
0x18104 MSS_CTRL_R5SS0_CORE0_TCM_ADDRPARITY_ERRAGG_STATUS rw — Status register based on mask for TCM address parity errors from R5SS0 CORE0.
  [2] R5SS0_CPU0_TCM_ADDRPARITY_ERRAGG_STATUS_R5SS0_CPU0_B1TCM0_PARITY_ERR — Status of Interrupt from address parity error of corresponding CPU*_TCM_ADDRPARITY_ERRAGG_MASK registerWrie 0x1 to clear this interrupt.
  [1] R5SS0_CPU0_TCM_ADDRPARITY_ERRAGG_STATUS_R5SS0_CPU0_B0TCM0_PARITY_ERR — Status of Interrupt from address parity error of corresponding CPU*_TCM_ADDRPARITY_ERRAGG_MASK registerWrie 0x1 to clear this interrupt.
  [0] R5SS0_CPU0_TCM_ADDRPARITY_ERRAGG_STATUS_R5SS0_CPU0_ATCM0_PARITY_ERR — Status of Interrupt from address parity error of corresponding CPU*_TCM_ADDRPARITY_ERRAGG_MASK registerWrie 0x1 to clear this interrupt.
0x18108 MSS_CTRL_R5SS0_CORE0_TCM_ADDRPARITY_ERRAGG_STATUS_RAW rw — Raw status for TCM address parity errors from R5SS0 CORE0.
  [2] R5SS0_CPU0_TCM_ADDRPARITY_ERRAGG_STATUS_RAW_R5SS0_CPU0_B1TCM0_PARITY_ERR — Raw Status of Interrupt from address parity error of corresponding CPU*_TCM_ADDRPARITY_ERRAGG_MASK registerWrie 0x1 to clear this interrupt.
  [1] R5SS0_CPU0_TCM_ADDRPARITY_ERRAGG_STATUS_RAW_R5SS0_CPU0_B0TCM0_PARITY_ERR — Raw Status of Interrupt from address parity error of corresponding CPU*_TCM_ADDRPARITY_ERRAGG_MASK registerWrie 0x1 to clear this interrupt.
  [0] R5SS0_CPU0_TCM_ADDRPARITY_ERRAGG_STATUS_RAW_R5SS0_CPU0_ATCM0_PARITY_ERR — Raw Status of Interrupt from address parity error of corresponding CPU*_TCM_ADDRPARITY_ERRAGG_MASK registerWrie 0x1 to clear this interrupt.
0x18110 MSS_CTRL_R5SS0_CORE1_TCM_ADDRPARITY_ERRAGG_MASK rw — Register to Mask TCM address parity errors from R5SS0 CORE1.
  [2] R5SS0_CPU1_TCM_ADDRPARITY_ERRAGG_MASK_R5SS0_CPU1_B1TCM1_PARITY_ERR — Mask Interrupt for address parity error s to aggregated Interrupt of corresponding CPU1'b1 : Interrupt is Masked1'b0 : Interrupt is Unmasked
  [1] R5SS0_CPU1_TCM_ADDRPARITY_ERRAGG_MASK_R5SS0_CPU1_B1TCM0_PARITY_ERR — Mask Interrupt for address parity error s to aggregated Interrupt of corresponding CPU1'b1 : Interrupt is Masked1'b0 : Interrupt is Unmasked
  [0] R5SS0_CPU1_TCM_ADDRPARITY_ERRAGG_MASK_R5SS0_CPU1_ATCM1_PARITY_ERR — Mask Interrupt for address parity error s to aggregated Interrupt of corresponding CPU1'b1 : Interrupt is Masked1'b0 : Interrupt is Unmasked
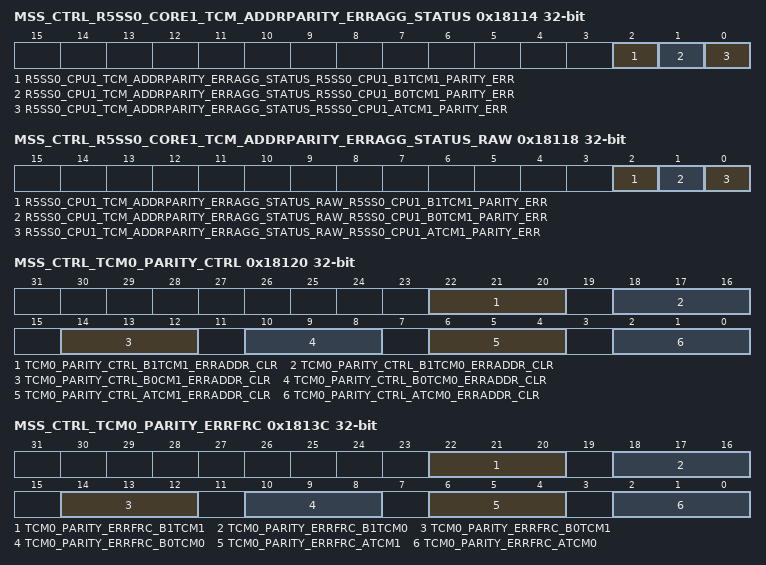
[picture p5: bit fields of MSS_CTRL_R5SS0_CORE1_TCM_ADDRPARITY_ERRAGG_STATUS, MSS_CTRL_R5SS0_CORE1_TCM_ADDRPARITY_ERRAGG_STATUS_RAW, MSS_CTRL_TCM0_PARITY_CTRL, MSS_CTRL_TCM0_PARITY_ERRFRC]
0x18114 MSS_CTRL_R5SS0_CORE1_TCM_ADDRPARITY_ERRAGG_STATUS rw — Status register based on mask for TCM address parity errors from R5SS0 CORE1.
  [2] R5SS0_CPU1_TCM_ADDRPARITY_ERRAGG_STATUS_R5SS0_CPU1_B1TCM1_PARITY_ERR — Status of Interrupt from address parity error of corresponding CPU*_TCM_ADDRPARITY_ERRAGG_MASK registerWrie 0x1 to clear this interrupt.
  [1] R5SS0_CPU1_TCM_ADDRPARITY_ERRAGG_STATUS_R5SS0_CPU1_B0TCM1_PARITY_ERR — Status of Interrupt from address parity error of corresponding CPU*_TCM_ADDRPARITY_ERRAGG_MASK registerWrie 0x1 to clear this interrupt.
  [0] R5SS0_CPU1_TCM_ADDRPARITY_ERRAGG_STATUS_R5SS0_CPU1_ATCM1_PARITY_ERR — Status of Interrupt from address parity error of corresponding CPU*_TCM_ADDRPARITY_ERRAGG_MASK registerWrie 0x1 to clear this interrupt.
0x18118 MSS_CTRL_R5SS0_CORE1_TCM_ADDRPARITY_ERRAGG_STATUS_RAW rw — Raw status for TCM address parity errors from R5SS0 CORE1.
  [2] R5SS0_CPU1_TCM_ADDRPARITY_ERRAGG_STATUS_RAW_R5SS0_CPU1_B1TCM1_PARITY_ERR — Raw Status of Interrupt from address parity error of corresponding CPU*_TCM_ADDRPARITY_ERRAGG_MASK registerWrie 0x1 to clear this interrupt.
  [1] R5SS0_CPU1_TCM_ADDRPARITY_ERRAGG_STATUS_RAW_R5SS0_CPU1_B0TCM1_PARITY_ERR — Raw Status of Interrupt from address parity error of corresponding CPU*_TCM_ADDRPARITY_ERRAGG_MASK registerWrie 0x1 to clear this interrupt.
  [0] R5SS0_CPU1_TCM_ADDRPARITY_ERRAGG_STATUS_RAW_R5SS0_CPU1_ATCM1_PARITY_ERR — Raw Status of Interrupt from address parity error of corresponding CPU*_TCM_ADDRPARITY_ERRAGG_MASK registerWrie 0x1 to clear this interrupt.
0x18120 MSS_CTRL_TCM0_PARITY_CTRL rw — This register clears the TCM Address Parity Errors of R5SS0.
  [22:20] TCM0_PARITY_CTRL_B1TCM1_ERRADDR_CLR — Write pulse bit field:Writing 3'b111 clears the Address latched after parity error for B1TCM of CR5B
  [18:16] TCM0_PARITY_CTRL_B1TCM0_ERRADDR_CLR — Write pulse bit field:Writing 3'b111 clears the Address latched after parity error for B1TCM of CR5A
  [14:12] TCM0_PARITY_CTRL_B0CM1_ERRADDR_CLR — Write pulse bit field:Writing 3'b111 clears the Address latched after parity error for B0TCM of CR5B
  [10:8] TCM0_PARITY_CTRL_B0TCM0_ERRADDR_CLR — Write pulse bit field:Writing 3'b111 clears the Address latched after parity error for B0TCM of CR5A
  [6:4] TCM0_PARITY_CTRL_ATCM1_ERRADDR_CLR — Write pulse bit field:Writing 3'b111 clears the Address latched after parity error for ATCM of CR5B
  [2:0] TCM0_PARITY_CTRL_ATCM0_ERRADDR_CLR — Pulse bit-field Writing 3'b111 clears the Address latched after parity error for ATCM of CR5A
0x18124 MSS_CTRL_ERR_PARITY_ATCM0_R5SS0 — This register latches the ATCM Address where the Address Parity Error occurred in R5SS0 CORE0.
  [19:0] ERR_PARITY_ATCM0_R5SS0_ADDR — Address lathched when parity error is occurred for ATCM of CR5A
0x18128 MSS_CTRL_ERR_PARITY_ATCM1_R5SS0 — This register latches the ATCM Address where the Address Parity Error occurred in R5SS0 CORE1.
  [19:0] ERR_PARITY_ATCM1_R5SS0_ADDR — Address lathched when parity error is occurred for ATCM of CR5B
0x1812C MSS_CTRL_ERR_PARITY_B0TCM0_R5SS0 — This register latches the B0TCM Address where the Address Parity Error occurred in R5SS0 CORE0.
  [19:0] ERR_PARITY_B0TCM0_R5SS0_ADDR — Address lathched when parity error is occurred for B0TCM of CR5A
0x18130 MSS_CTRL_ERR_PARITY_B0TCM1_R5SS0 — This register latches the B0TCM Address where the Address Parity Error occurred in R5SS0 CORE1.
  [19:0] ERR_PARITY_B0TCM1_R5SS0_ADDR — Address lathched when parity error is occurred for B0TCM of CR5B
0x18134 MSS_CTRL_ERR_PARITY_B1TCM0_R5SS0 — This register latches the B1TCM Address where the Address Parity Error occurred in R5SS0 CORE0.
  [19:0] ERR_PARITY_B1TCM0_R5SS0_ADDR — Address lathched when parity error is occurred for B1TCM of CR5A
0x18138 MSS_CTRL_ERR_PARITY_B1TCM1_R5SS0 — This register latches the B1TCM Address where the Address Parity Error occurred in R5SS0 CORE1.
  [19:0] ERR_PARITY_B1TCM1_R5SS0_ADDR — Address lathched when parity error is occurred for B1TCM of CR5B
0x1813C MSS_CTRL_TCM0_PARITY_ERRFRC rw — This register is used to Inject fault in the TCM Address Parity Error detection logic of R5SS0 .
  [22:20] TCM0_PARITY_ERRFRC_B1TCM1 — Write pulse bit field:Writing 3'b111 forces a parity error for B1TCM of CR5B
  [18:16] TCM0_PARITY_ERRFRC_B1TCM0 — Write pulse bit field:Writing 3'b111 forces a parity error for B1TCM of CR5A
  [14:12] TCM0_PARITY_ERRFRC_B0TCM1 — Write pulse bit field:Writing 3'b111 forces a parity error for B0TCM of CR5B
  [10:8] TCM0_PARITY_ERRFRC_B0TCM0 — Write pulse bit field:Writing 3'b111 forces a parity error for B0TCM of CR5A
  [6:4] TCM0_PARITY_ERRFRC_ATCM1 — Write pulse bit field:Writing 3'b111 forces a parity error for ATCM of CR5B
  [2:0] TCM0_PARITY_ERRFRC_ATCM0 — Write pulse bit field:Writing 3'b111 forces a parity error for ATCM of CR5A
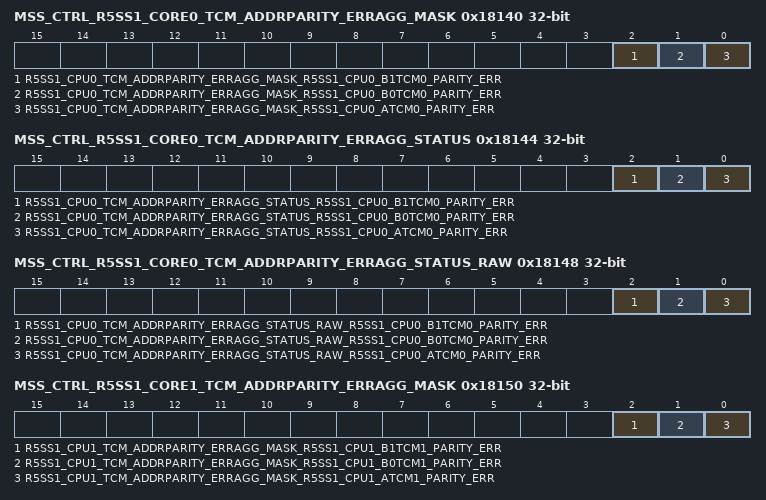
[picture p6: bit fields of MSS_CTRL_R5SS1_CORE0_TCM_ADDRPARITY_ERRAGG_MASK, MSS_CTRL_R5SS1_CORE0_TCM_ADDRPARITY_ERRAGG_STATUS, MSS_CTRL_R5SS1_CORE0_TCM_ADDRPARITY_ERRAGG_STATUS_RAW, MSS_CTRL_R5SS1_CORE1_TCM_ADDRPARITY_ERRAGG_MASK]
0x18140 MSS_CTRL_R5SS1_CORE0_TCM_ADDRPARITY_ERRAGG_MASK rw — Register to Mask TCM address parity errors from R5SS1 CORE0.
  [2] R5SS1_CPU0_TCM_ADDRPARITY_ERRAGG_MASK_R5SS1_CPU0_B1TCM0_PARITY_ERR — Mask Interrupt for address parity error s to aggregated Interrupt of corresponding CPU1'b1 : Interrupt is Masked1'b0 : Interrupt is Unmasked
  [1] R5SS1_CPU0_TCM_ADDRPARITY_ERRAGG_MASK_R5SS1_CPU0_B0TCM0_PARITY_ERR — Mask Interrupt for address parity error s to aggregated Interrupt of corresponding CPU1'b1 : Interrupt is Masked1'b0 : Interrupt is Unmasked
  [0] R5SS1_CPU0_TCM_ADDRPARITY_ERRAGG_MASK_R5SS1_CPU0_ATCM0_PARITY_ERR — Mask Interrupt for address parity error s to aggregated Interrupt of corresponding CPU1'b1 : Interrupt is Masked1'b0 : Interrupt is Unmasked
0x18144 MSS_CTRL_R5SS1_CORE0_TCM_ADDRPARITY_ERRAGG_STATUS rw — Status register based on mask for TCM address parity errors from R5SS1 CORE0.
  [2] R5SS1_CPU0_TCM_ADDRPARITY_ERRAGG_STATUS_R5SS1_CPU0_B1TCM0_PARITY_ERR — Status of Interrupt from address parity error of corresponding CPU*_TCM_ADDRPARITY_ERRAGG_MASK registerWrie 0x1 to clear this interrupt.
  [1] R5SS1_CPU0_TCM_ADDRPARITY_ERRAGG_STATUS_R5SS1_CPU0_B0TCM0_PARITY_ERR — Status of Interrupt from address parity error of corresponding CPU*_TCM_ADDRPARITY_ERRAGG_MASK registerWrie 0x1 to clear this interrupt.
  [0] R5SS1_CPU0_TCM_ADDRPARITY_ERRAGG_STATUS_R5SS1_CPU0_ATCM0_PARITY_ERR — Status of Interrupt from address parity error of corresponding CPU*_TCM_ADDRPARITY_ERRAGG_MASK registerWrie 0x1 to clear this interrupt.
0x18148 MSS_CTRL_R5SS1_CORE0_TCM_ADDRPARITY_ERRAGG_STATUS_RAW rw — Raw status for TCM address parity errors from R5SS1 CORE0.
  [2] R5SS1_CPU0_TCM_ADDRPARITY_ERRAGG_STATUS_RAW_R5SS1_CPU0_B1TCM0_PARITY_ERR — Raw Status of Interrupt from address parity error of corresponding CPU*_TCM_ADDRPARITY_ERRAGG_MASK registerWrie 0x1 to clear this interrupt.
  [1] R5SS1_CPU0_TCM_ADDRPARITY_ERRAGG_STATUS_RAW_R5SS1_CPU0_B0TCM0_PARITY_ERR — Raw Status of Interrupt from address parity error of corresponding CPU*_TCM_ADDRPARITY_ERRAGG_MASK registerWrie 0x1 to clear this interrupt.
  [0] R5SS1_CPU0_TCM_ADDRPARITY_ERRAGG_STATUS_RAW_R5SS1_CPU0_ATCM0_PARITY_ERR — Raw Status of Interrupt from address parity error of corresponding CPU*_TCM_ADDRPARITY_ERRAGG_MASK registerWrie 0x1 to clear this interrupt.
0x18150 MSS_CTRL_R5SS1_CORE1_TCM_ADDRPARITY_ERRAGG_MASK rw — Register to Mask TCM address parity errors from R5SS1 CORE1.
  [2] R5SS1_CPU1_TCM_ADDRPARITY_ERRAGG_MASK_R5SS1_CPU1_B1TCM1_PARITY_ERR — Mask Interrupt for address parity error s to aggregated Interrupt of corresponding CPU1'b1 : Interrupt is Masked1'b0 : Interrupt is Unmasked
  [1] R5SS1_CPU1_TCM_ADDRPARITY_ERRAGG_MASK_R5SS1_CPU1_B0TCM1_PARITY_ERR — Mask Interrupt for address parity error s to aggregated Interrupt of corresponding CPU1'b1 : Interrupt is Masked1'b0 : Interrupt is Unmasked
  [0] R5SS1_CPU1_TCM_ADDRPARITY_ERRAGG_MASK_R5SS1_CPU1_ATCM1_PARITY_ERR — Mask Interrupt for address parity error s to aggregated Interrupt of corresponding CPU1'b1 : Interrupt is Masked1'b0 : Interrupt is Unmasked
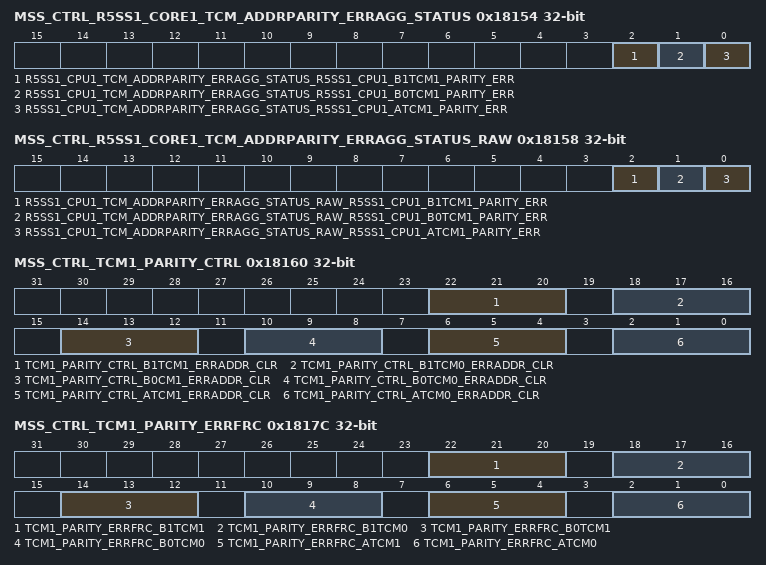
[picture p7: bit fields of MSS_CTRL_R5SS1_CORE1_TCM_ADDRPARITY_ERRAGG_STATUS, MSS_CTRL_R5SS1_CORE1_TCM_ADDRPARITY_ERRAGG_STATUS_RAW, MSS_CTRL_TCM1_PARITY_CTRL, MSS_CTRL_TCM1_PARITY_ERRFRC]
0x18154 MSS_CTRL_R5SS1_CORE1_TCM_ADDRPARITY_ERRAGG_STATUS rw — Status register based on mask for TCM address parity errors from R5SS1 CORE1.
  [2] R5SS1_CPU1_TCM_ADDRPARITY_ERRAGG_STATUS_R5SS1_CPU1_B1TCM1_PARITY_ERR — Status of Interrupt from address parity error of corresponding CPU*_TCM_ADDRPARITY_ERRAGG_MASK registerWrie 0x1 to clear this interrupt.
  [1] R5SS1_CPU1_TCM_ADDRPARITY_ERRAGG_STATUS_R5SS1_CPU1_B0TCM1_PARITY_ERR — Status of Interrupt from address parity error of corresponding CPU*_TCM_ADDRPARITY_ERRAGG_MASK registerWrie 0x1 to clear this interrupt.
  [0] R5SS1_CPU1_TCM_ADDRPARITY_ERRAGG_STATUS_R5SS1_CPU1_ATCM1_PARITY_ERR — Status of Interrupt from address parity error of corresponding CPU*_TCM_ADDRPARITY_ERRAGG_MASK registerWrie 0x1 to clear this interrupt.
0x18158 MSS_CTRL_R5SS1_CORE1_TCM_ADDRPARITY_ERRAGG_STATUS_RAW rw — Raw status for TCM address parity errors from R5SS1 CORE1.
  [2] R5SS1_CPU1_TCM_ADDRPARITY_ERRAGG_STATUS_RAW_R5SS1_CPU1_B1TCM1_PARITY_ERR — Raw Status of Interrupt from address parity error of corresponding CPU*_TCM_ADDRPARITY_ERRAGG_MASK registerWrie 0x1 to clear this interrupt.
  [1] R5SS1_CPU1_TCM_ADDRPARITY_ERRAGG_STATUS_RAW_R5SS1_CPU1_B0TCM1_PARITY_ERR — Raw Status of Interrupt from address parity error of corresponding CPU*_TCM_ADDRPARITY_ERRAGG_MASK registerWrie 0x1 to clear this interrupt.
  [0] R5SS1_CPU1_TCM_ADDRPARITY_ERRAGG_STATUS_RAW_R5SS1_CPU1_ATCM1_PARITY_ERR — Raw Status of Interrupt from address parity error of corresponding CPU*_TCM_ADDRPARITY_ERRAGG_MASK registerWrie 0x1 to clear this interrupt.
0x18160 MSS_CTRL_TCM1_PARITY_CTRL rw — This register clears the TCM Address Parity Errors of R5SS1.
  [22:20] TCM1_PARITY_CTRL_B1TCM1_ERRADDR_CLR — Write pulse bit field:Writing 3'b111 clears the Address latched after parity error for B1TCM of CR5B
  [18:16] TCM1_PARITY_CTRL_B1TCM0_ERRADDR_CLR — Write pulse bit field:Writing 3'b111 clears the Address latched after parity error for B1TCM of CR5A
  [14:12] TCM1_PARITY_CTRL_B0CM1_ERRADDR_CLR — Write pulse bit field:Writing 3'b111 clears the Address latched after parity error for B0TCM of CR5B
  [10:8] TCM1_PARITY_CTRL_B0TCM0_ERRADDR_CLR — Write pulse bit field:Writing 3'b111 clears the Address latched after parity error for B0TCM of CR5A
  [6:4] TCM1_PARITY_CTRL_ATCM1_ERRADDR_CLR — Write pulse bit field:Writing 3'b111 clears the Address latched after parity error for ATCM of CR5B
  [2:0] TCM1_PARITY_CTRL_ATCM0_ERRADDR_CLR — Pulse bit-field Writing 3'b111 clears the Address latched after parity error for ATCM of CR5A
0x18164 MSS_CTRL_ERR_PARITY_ATCM0_R5SS1 — This register latches the ATCM Address where the Address Parity Error occurred in R5SS1 CORE0.
  [19:0] ERR_PARITY_ATCM0_R5SS1_ADDR — Address lathched when parity error is occurred for ATCM of CR5A
0x18168 MSS_CTRL_ERR_PARITY_ATCM1_R5SS1 — This register latches the ATCM Address where the Address Parity Error occurred in R5SS1 CORE1.
  [19:0] ERR_PARITY_ATCM1_R5SS1_ADDR — Address lathched when parity error is occurred for ATCM of CR5B
0x1816C MSS_CTRL_ERR_PARITY_B0TCM0_R5SS1 — This register latches the B0TCM Address where the Address Parity Error occurred in R5SS1 CORE0.
  [19:0] ERR_PARITY_B0TCM0_R5SS1_ADDR — Address lathched when parity error is occurred for B0TCM of CR5A
0x18170 MSS_CTRL_ERR_PARITY_B0TCM1_R5SS1 — This register latches the B0TCM Address where the Address Parity Error occurred in R5SS1 CORE1.
  [19:0] ERR_PARITY_B0TCM1_R5SS1_ADDR — Address lathched when parity error is occurred for B0TCM of CR5B
0x18174 MSS_CTRL_ERR_PARITY_B1TCM0_R5SS1 — This register latches the B1TCM Address where the Address Parity Error occurred in R5SS1 CORE0.
  [19:0] ERR_PARITY_B1TCM0_R5SS1_ADDR — Address lathched when parity error is occurred for B1TCM of CR5A
0x18178 MSS_CTRL_ERR_PARITY_B1TCM1_R5SS1 — This register latches the B1TCM Address where the Address Parity Error occurred in R5SS1 CORE1.
  [19:0] ERR_PARITY_B1TCM1_R5SS1_ADDR — Address lathched when parity error is occurred for B1TCM of CR5B
0x1817C MSS_CTRL_TCM1_PARITY_ERRFRC rw — This register is used to Inject fault in the TCM Address Parity Error detection logic of R5SS1 .
  [22:20] TCM1_PARITY_ERRFRC_B1TCM1 — Write pulse bit field:Writing 3'b111 forces a parity error for B1TCM of CR5B
  [18:16] TCM1_PARITY_ERRFRC_B1TCM0 — Write pulse bit field:Writing 3'b111 forces a parity error for B1TCM of CR5A
  [14:12] TCM1_PARITY_ERRFRC_B0TCM1 — Write pulse bit field:Writing 3'b111 forces a parity error for B0TCM of CR5B
  [10:8] TCM1_PARITY_ERRFRC_B0TCM0 — Write pulse bit field:Writing 3'b111 forces a parity error for B0TCM of CR5A
  [6:4] TCM1_PARITY_ERRFRC_ATCM1 — Write pulse bit field:Writing 3'b111 forces a parity error for ATCM of CR5B
  [2:0] TCM1_PARITY_ERRFRC_ATCM0 — Write pulse bit field:Writing 3'b111 forces a parity error for ATCM of CR5A
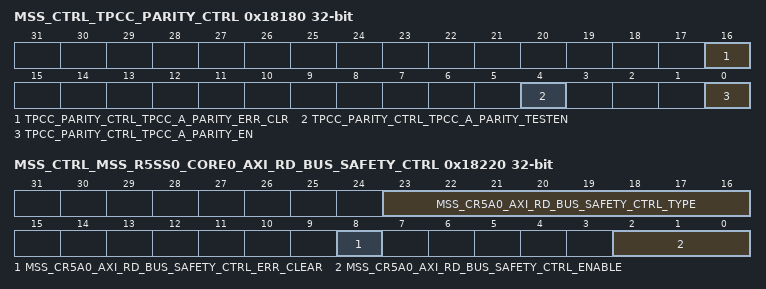
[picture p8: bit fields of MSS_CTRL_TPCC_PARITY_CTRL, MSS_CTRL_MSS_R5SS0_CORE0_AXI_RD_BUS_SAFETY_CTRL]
0x18180 MSS_CTRL_TPCC_PARITY_CTRL rw — This register Controls the Parity Error detection logic of EDMA TPCC0 Memories.
  [16] TPCC_PARITY_CTRL_TPCC_A_PARITY_ERR_CLR — Write pulse bit field:parity clear bit. Writing 1'b1 will clear the tpcc_a_parity_addr
  [4] TPCC_PARITY_CTRL_TPCC_A_PARITY_TESTEN — parity test enable for tpcc a
  [0] TPCC_PARITY_CTRL_TPCC_A_PARITY_EN — Writing 1'b1 enables parity for TPCC_A
0x18184 MSS_CTRL_TPCC_PARITY_STATUS — This register indicates the Address where the Parity Error occurred in TPCC0 Memory.
  [8:0] TPCC_PARITY_STATUS_TPCC_A_PARITY_ADDR — Address where parity error happened for tpcca
0x18200 MSS_CTRL_MSS_BUS_SAFETY_CTRL rw — This register is used to Globally enable Interconnect Safety.
  [2:0] MSS_BUS_SAFETY_CTRL_ENABLE — Set this bit to 3'b111 to Globally enable Interconnect Safety. Set this bit to 3'b000 to globally disable the Interconnect safety.
0x18220 MSS_CTRL_MSS_R5SS0_CORE0_AXI_RD_BUS_SAFETY_CTRL access per field — This register is used to Control and Configure the Interconnect Safety Behaviour of R5SS0 CORE0 AXI RD Initiator Port.
  [23:16] MSS_CR5A0_AXI_RD_BUS_SAFETY_CTRL_TYPE ro — This bitfield gives a top level idea of the available bus [cmd,wr,ws,rd] for the particular Target/Initiator and whether it follows the VBUS protocol or not. Bit 0 - 1'b1 indicates the Command bus is implemented to this target/initiator else it is set to 1'b0. Bit 1 - 1'b1 indicates the write bus is implemented to this target/initiator else it is set to 1'b0. Bit 2 - 1'b1 indicates the write status bus is implemented to this target/initiator else it is set to 1'b0. Bit 3 - 1'b1 indicates the read bus is implemented to this target/initiator else it is set to 1'b0. Bit 4 - 1'b0 indicates the port follows the VBUS protocol else it is set to 1'b1. Bits 5-7 are set to 3'b000.
  [8] MSS_CR5A0_AXI_RD_BUS_SAFETY_CTRL_ERR_CLEAR rw — Set this bit to 1'b1 to clear the error status for this port
  [2:0] MSS_CR5A0_AXI_RD_BUS_SAFETY_CTRL_ENABLE rw — Set this bit to 3'b111 to enable the safety configuration for this port. Set this bit to 3'b000 to disable the safety configuration for this port.
